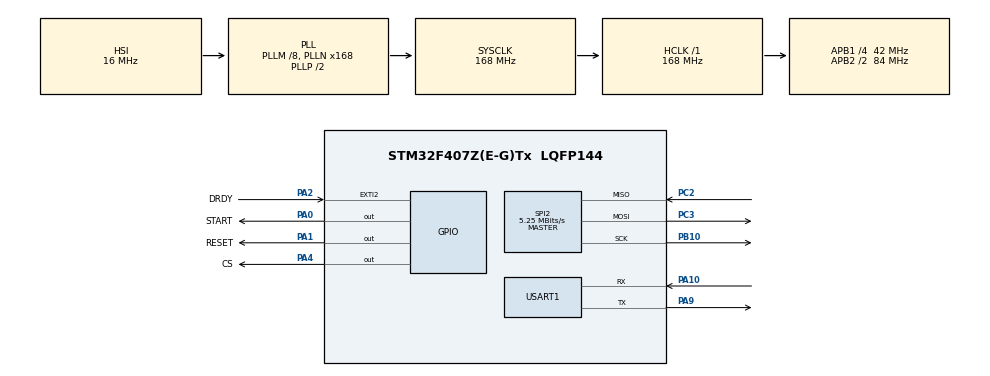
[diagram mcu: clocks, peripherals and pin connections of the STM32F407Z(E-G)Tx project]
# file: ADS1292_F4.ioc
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Mcu.Family=STM32F4
Mcu.Name=STM32F407Z(E-G)Tx
Mcu.Package=LQFP144
NVIC.EXTI2_IRQn=true\:1\:0\:true\:false\:true\:true\:true
NVIC.PriorityGroup=NVIC_PRIORITYGROUP_4
PA0-WKUP.GPIO_Label=START
PA0-WKUP.Signal=GPIO_Output
PA1.GPIO_Label=RESET
PA1.Signal=GPIO_Output
PA10.Mode=Asynchronous
PA10.Signal=USART1_RX
PA13.Mode=Serial_Wire
PA13.Signal=SYS_JTMS-SWDIO
PA14.Mode=Serial_Wire
PA14.Signal=SYS_JTCK-SWCLK
PA2.GPIO_Label=DRDY
PA2.GPIO_ModeDefaultEXTI=GPIO_MODE_IT_FALLING
PA2.Signal=GPXTI2
PA4.GPIO_Label=CS
PA4.Signal=GPIO_Output
PA9.Mode=Asynchronous
PA9.Signal=USART1_TX
PB10.Mode=Full_Duplex_Master
PB10.Signal=SPI2_SCK
PC2.Mode=Full_Duplex_Master
PC2.Signal=SPI2_MISO
PC3.Mode=Full_Duplex_Master
PC3.Signal=SPI2_MOSI
PH0-OSC_IN.Mode=HSE-External-Oscillator
PH0-OSC_IN.Signal=RCC_OSC_IN
PH1-OSC_OUT.Mode=HSE-External-Oscillator
PH1-OSC_OUT.Signal=RCC_OSC_OUT
ProjectManager.HeapSize=0x200
ProjectManager.StackSize=0x400
ProjectManager.TargetToolchain=MDK-ARM V5.27
RCC.48MHZClocksFreq_Value=84000000
RCC.AHBFreq_Value=168000000
RCC.APB1CLKDivider=RCC_HCLK_DIV4
RCC.APB1Freq_Value=42000000
RCC.APB1TimFreq_Value=84000000
RCC.APB2CLKDivider=RCC_HCLK_DIV2
RCC.APB2Freq_Value=84000000
RCC.APB2TimFreq_Value=168000000
RCC.CortexFreq_Value=168000000
RCC.HCLKFreq_Value=168000000
RCC.HSE_VALUE=8000000
RCC.HSI_VALUE=16000000
RCC.LSE_VALUE=32768
RCC.PLLM=8
RCC.PLLN=168
RCC.SYSCLKFreq_VALUE=168000000
RCC.SYSCLKSource=RCC_SYSCLKSOURCE_PLLCLK
RCC.VCOOutputFreq_Value=336000000
SPI2.BaudRatePrescaler=SPI_BAUDRATEPRESCALER_8
SPI2.CLKPhase=SPI_PHASE_2EDGE
SPI2.CRCCalculation=SPI_CRCCALCULATION_DISABLE
SPI2.CalculateBaudRate=5.25 MBits/s
SPI2.Direction=SPI_DIRECTION_2LINES
SPI2.Mode=SPI_MODE_MASTER
SPI2.VirtualType=VM_MASTER
TIM7.Period=1-1
TIM7.Prescaler=84-1
USART1.VirtualMode=VM_ASYNC
VP_TIM7_VS_ClockSourceINT.Mode=Enable_Timer
board=custom

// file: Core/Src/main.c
/* USER CODE BEGIN Header */
/**
  ******************************************************************************
  * @file           : main.c
  * @brief          : Main program body
  ******************************************************************************
  * @attention
  *
  * <h2><center>&copy; Copyright (c) 2020 STMicroelectronics.
  * All rights reserved.</center></h2>
  *
  * This software component is licensed by ST under BSD 3-Clause license,
  * the "License"; You may not use this file except in compliance with the
  * License. You may obtain a copy of the License at:
  *                        opensource.org/licenses/BSD-3-Clause
  *
  ******************************************************************************
  */
/* USER CODE END Header */
#include "main.h"
#include "spi.h"
#include "tim.h"
#include "usart.h"
#include "gpio.h"

/* USER CODE BEGIN Includes */
#include "ads1292r.h"
/* USER CODE END Includes */

/* USER CODE BEGIN PV */
int recv_flag = 0;

uint8_t sspi[9] = {0,1,2,3,4,5,6,7,8};
/* USER CODE END PV */

void SystemClock_Config(void);

int main(void)
{

  /* MCU Configuration--------------------------------------------------------*/

  /* Reset of all peripherals, Initializes the Flash interface and the Systick. */
  HAL_Init();

  /* Configure the system clock */
  SystemClock_Config();

  /* Initialize all configured peripherals */
  MX_GPIO_Init();
  MX_USART1_UART_Init();
  MX_SPI2_Init();
  MX_TIM7_Init();
  /* USER CODE BEGIN 2 */
//  ADS1292R_Init();
//  ADS1292R_PowerOnInit();
//  ADS1292R_Work();
  /* USER CODE END 2 */

  /* Infinite loop */
  while (1)
  {

    /* USER CODE BEGIN 3 */
		HAL_SPI_Transmit(&hspi2,sspi,9,20);
    if (recv_flag == 1)
    {
      HAL_UART_Transmit(&huart1,ads1292r_data_buff,9,10);
      recv_flag = 0;
    }
    HAL_Delay(50);
  }
  /* USER CODE END 3 */
}

void SystemClock_Config(void)
{
  RCC_OscInitTypeDef RCC_OscInitStruct = {0};
  RCC_ClkInitTypeDef RCC_ClkInitStruct = {0};

  /** Configure the main internal regulator output voltage
  */
  __HAL_RCC_PWR_CLK_ENABLE();
  __HAL_PWR_VOLTAGESCALING_CONFIG(PWR_REGULATOR_VOLTAGE_SCALE1);
  /** Initializes the RCC Oscillators according to the specified parameters
  * in the RCC_OscInitTypeDef structure.
  */
  RCC_OscInitStruct.OscillatorType = RCC_OSCILLATORTYPE_HSI;
  RCC_OscInitStruct.HSIState = RCC_HSI_ON;
  RCC_OscInitStruct.HSICalibrationValue = RCC_HSICALIBRATION_DEFAULT;
  RCC_OscInitStruct.PLL.PLLState = RCC_PLL_ON;
  RCC_OscInitStruct.PLL.PLLSource = RCC_PLLSOURCE_HSI;
  RCC_OscInitStruct.PLL.PLLM = 8;
  RCC_OscInitStruct.PLL.PLLN = 168;
  RCC_OscInitStruct.PLL.PLLP = RCC_PLLP_DIV2;
  RCC_OscInitStruct.PLL.PLLQ = 4;
  if (HAL_RCC_OscConfig(&RCC_OscInitStruct) != HAL_OK)
  {
    Error_Handler();
  }
  /** Initializes the CPU, AHB and APB buses clocks
  */
  RCC_ClkInitStruct.ClockType = RCC_CLOCKTYPE_HCLK|RCC_CLOCKTYPE_SYSCLK
                              |RCC_CLOCKTYPE_PCLK1|RCC_CLOCKTYPE_PCLK2;
  RCC_ClkInitStruct.SYSCLKSource = RCC_SYSCLKSOURCE_PLLCLK;
  RCC_ClkInitStruct.AHBCLKDivider = RCC_SYSCLK_DIV1;
  RCC_ClkInitStruct.APB1CLKDivider = RCC_HCLK_DIV4;
  RCC_ClkInitStruct.APB2CLKDivider = RCC_HCLK_DIV2;

  if (HAL_RCC_ClockConfig(&RCC_ClkInitStruct, FLASH_LATENCY_5) != HAL_OK)
  {
    Error_Handler();
  }
}

/* USER CODE BEGIN 4 */

void HAL_GPIO_EXTI_Callback(uint16_t GPIO_Pin)
{
  if (GPIO_Pin == GPIO_PIN_2)
  {
    if (HAL_GPIO_ReadPin(DRDY_GPIO_Port,DRDY_Pin) == GPIO_PIN_RESET)
    {
      ADS1292R_ReadData();
      recv_flag = 1;
    }

  }

}

/* USER CODE END 4 */

void Error_Handler(void)
{
}

/************************ (C) COPYRIGHT STMicroelectronics *****END OF FILE****/
